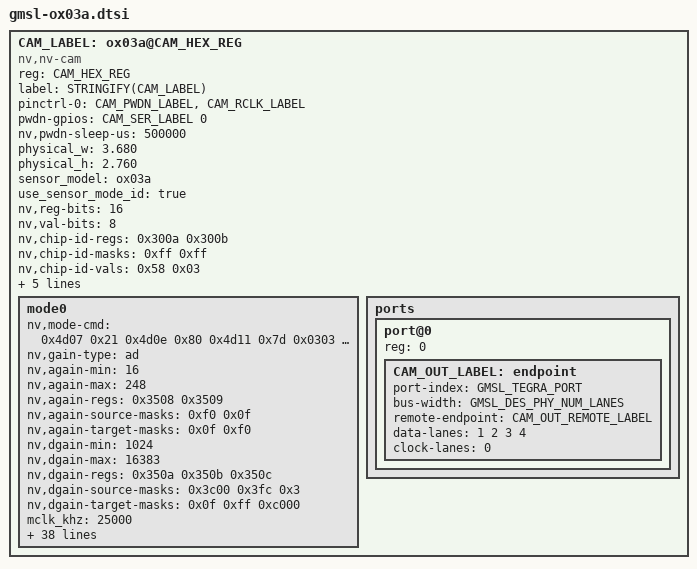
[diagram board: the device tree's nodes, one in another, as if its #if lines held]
// SPDX-License-Identifier: GPL-2.0
/*
 * Copyright (C) 2023 Analog Devices Inc.
 */

#include <dt-bindings/media/camera.h>

#if defined(CAM_INDEX)
#define CAM_VC_ID		CAM_INDEX
#define CAM_SER_INDEX		CAM_INDEX
#define CAM_SER_LABEL		CONCAT(ser_, CAM_SER_INDEX)
#define CAM_PWDN_LABEL		CONCAT(CAM_SER_LABEL, _mfp0_pwdn)
#define CAM_RCLK_LABEL		CONCAT(CAM_SER_LABEL, _mfp4_rclk)
#define CAM_OUT_LABEL		CAM_X_OUT_LABEL(CAM_INDEX)
#define CAM_LABEL		CONCAT(cam_, CAM_INDEX)
#endif

#if defined(SER_INDEX) && defined(SER_CH_INDEX)
#define CAM_OUT_REMOTE_LABEL	SER_X_CH_Y_IN_LABEL(SER_INDEX, SER_CH_INDEX)
#endif

#if !defined(CAM_HEX_REG)
#error
#endif

#if !defined(CAM_VC_ID)
#error
#endif

#if !defined(CAM_SER_LABEL)
#error
#endif

#if !defined(CAM_PWDN_LABEL)
#error
#endif

#if !defined(CAM_RCLK_LABEL)
#error
#endif

#if !defined(CAM_OUT_LABEL)
#error
#endif

#if !defined(CAM_OUT_REMOTE_LABEL)
#error
#endif

#if !defined(CAM_LABEL)
#error
#endif

// #define CAM_USE_AD_GAIN

CAM_LABEL: ox03a@CAM_HEX_REG {
	#address-cells = <1>;
	#size-cells = <0>;

	compatible = "nv,nv-cam";
	reg = <CAM_HEX_REG>;

	label = STRINGIFY(CAM_LABEL);

	pinctrl-0 = <&CAM_PWDN_LABEL &CAM_RCLK_LABEL>;
	pinctrl-names = "default";

	pwdn-gpios = <&CAM_SER_LABEL 0 GPIO_ACTIVE_HIGH>;
	nv,pwdn-sleep-us = <500000>;

	physical_w = "3.680";
	physical_h = "2.760";

	sensor_model = "ox03a";

	use_sensor_mode_id = "true";

	nv,reg-bits = <16>;
	nv,val-bits = <8>;

	nv,chip-id-regs = <0x300a 0x300b>;
	nv,chip-id-masks = <0xff 0xff>;
	nv,chip-id-vals = <0x58 0x03>;

	nv,wait-ms-cmd = <0x00>;

	nv,mode-common-cmd = <
		0x0100 0x00 /* Stream off */
		0x0103 0x01 /* SW reset */
		0x00   10   /* Wait 10ms */
	>;
	nv,start-stream-cmd = <
		0x0100 0x01 /* Stream on */
		0x00   3    /* Wait 3ms */
	>;
	nv,stop-stream-cmd = <0x0100 0x00>;

	mode0 {
		nv,mode-cmd = <
			0x4d07 0x21
			0x4d0e 0x80
			0x4d11 0x7d
			0x0303 0x02
			0x0305 0x30
			0x0306 0x03
			0x0307 0x01
			0x0316 0x00
			0x0317 0x42
			0x0323 0x02
			0x0325 0x68
			0x0326 0x00
			0x032b 0x00
			0x0400 0xe7
			0x0401 0xff
			0x0404 0x2b
			0x0405 0x32
			0x0406 0x33
			0x0407 0x8f
			0x0408 0x0c
			0x0410 0xe7
			0x0411 0xff
			0x0414 0x2b
			0x0415 0x32
			0x0416 0x33
			0x0417 0x8f
			0x0418 0x0c
			0x3002 0x03
			0x3012 0x41
			0x301e 0xb0
			0x3706 0x39
			0x370a 0x00
			0x370b 0xd1
			0x370f 0x40
			0x3711 0x22
			0x3712 0x12
			0x3713 0x00
			0x3718 0x04
			0x3719 0x3c
			0x371a 0x06
			0x371b 0x14
			0x372c 0x17
			0x3733 0x41
			0x3741 0x44
			0x3742 0x34
			0x3746 0x03
			0x374b 0x03
			0x3755 0x09
			0x376c 0x04
			0x376d 0x08
			0x376f 0x08
			0x3770 0x91
			0x3771 0x08
			0x3774 0x8a
			0x3777 0x99
			0x3779 0x22
			0x377a 0x00
			0x377b 0x00
			0x377c 0x48
			0x3785 0x08
			0x3790 0x10
			0x3793 0x00
			0x379c 0x01
			0x37a1 0x80
			0x37b3 0x0a
			0x37be 0x01
			0x37bf 0x01
			0x37c6 0x48
			0x37c7 0x38
			0x37c9 0x00
			0x37ca 0x39
			0x37cb 0x00
			0x37cc 0xa3
			0x37d1 0x39
			0x37d2 0x00
			0x37d3 0xa3
			0x37d5 0x39
			0x37d6 0x00
			0x37d7 0xa3
			0x3c06 0x29
			0x3c0b 0xa8
			0x3c53 0x68
			0x3192 0x00
			0x3193 0x00
			0x3206 0x80
			0x3216 0x01
			0x3400 0x08
			0x3409 0x02
			0x3501 0x00
			0x3502 0x40
			0x3508 0x01
			0x3509 0x00
			0x350a 0x01
			0x350b 0x00
			0x350c 0x00
			0x3548 0x01
			0x3549 0x00
			0x354a 0x01
			0x354b 0x00
			0x354c 0x00
			0x3581 0x00
			0x3582 0x40
			0x3588 0x01
			0x3589 0x00
			0x358a 0x01
			0x358b 0x00
			0x358c 0x00
			0x3600 0x00
			0x3602 0x42
			0x3603 0xf3
			0x3604 0x93
			0x3605 0xff
			0x3606 0xc0
			0x3607 0x4a
			0x360a 0xd0
			0x360b 0x0b
			0x360e 0x88
			0x3611 0x4b
			0x3612 0x4e
			0x3614 0x8a
			0x3615 0x98
			0x3619 0x00
			0x3620 0x02
			0x3626 0x0e
			0x362c 0x0e
			0x362d 0x12
			0x362e 0x0b
			0x362f 0x18
			0x3630 0x30
			0x3631 0x57
			0x3632 0x99
			0x3633 0x99
			0x3643 0x0c
			0x3644 0x00
			0x3645 0x0e
			0x3646 0x0f
			0x3647 0x0e
			0x3648 0x00
			0x3649 0x11
			0x364a 0x12
			0x364c 0x0e
			0x364d 0x0e
			0x364e 0x12
			0x364f 0x0e
			0x3652 0xc5
			0x3657 0x88
			0x3658 0x08
			0x365a 0x57
			0x365b 0x30
			0x365c 0x18
			0x365d 0x0b
			0x3660 0x01
			0x3661 0x07
			0x3662 0x00
			0x3665 0x92
			0x3666 0x13
			0x3667 0x2c
			0x3668 0x95
			0x3669 0x2c
			0x366f 0xc4
			0x3671 0x0b
			0x3673 0x6a
			0x3678 0x88
			0x3800 0x00
			0x3801 0x00
			0x3802 0x00
			0x3803 0x04
			0x3804 0x07
			0x3805 0x8f
			0x3806 0x05
			0x3807 0x0b
			0x3808 0x07
			0x3809 0x80
			0x380a 0x05
			0x380b 0x00
			0x380c 0x0a
			0x380d 0x90
			0x380e 0x05
			0x380f 0x37
			0x3810 0x00
			0x3811 0x08
			0x3813 0x04
			0x381c 0x00
			0x3820 0x44
			0x3821 0x00
			0x3822 0x14
			0x3832 0x10
			0x3833 0x01
			0x3834 0xf0
			0x383d 0x20
			0x384c 0x02
			0x384d 0x14
			0x384e 0x00
			0x384f 0x40
			0x3850 0x00
			0x3851 0x42
			0x3852 0x00
			0x3853 0x40
			0x3854 0x00
			0x3855 0x05
			0x3856 0x05
			0x3857 0x33
			0x3858 0x3c
			0x3859 0x00
			0x385a 0x03
			0x385b 0x05
			0x385c 0x32
			0x385f 0x00
			0x3860 0x10
			0x3861 0x00
			0x3862 0x40
			0x3863 0x00
			0x3864 0x40
			0x3865 0x00
			0x3866 0x40
			0x3b40 0x3e
			0x3b41 0x00
			0x3b42 0x02
			0x3b43 0x00
			0x3b44 0x00
			0x3b45 0x20
			0x3b46 0x00
			0x3b47 0x20
			0x3b84 0x05
			0x3b85 0x00
			0x3b86 0x00
			0x3b87 0x10
			0x3b88 0x00
			0x3b89 0x10
			0x3b8a 0x00
			0x3b8b 0x08
			0x3b8e 0x03
			0x3b8f 0xe8
			0x3d85 0x0b
			0x3d8c 0x70
			0x3d8d 0x26
			0x3d97 0x70
			0x3d98 0x24
			0x3d99 0x70
			0x3d9a 0x6d
			0x3d9b 0x70
			0x3d9c 0x6e
			0x3d9d 0x73
			0x3d9e 0xff
			0x3f00 0x04
			0x4001 0x2b
			0x4004 0x00
			0x4005 0x80
			0x4008 0x02
			0x4009 0x0d
			0x400a 0x10
			0x400b 0x80
			0x400f 0x80
			0x4010 0x10
			0x4011 0xbb
			0x4016 0x00
			0x4017 0x10
			0x402e 0x00
			0x402f 0x80
			0x4030 0x00
			0x4031 0x80
			0x4032 0x9f
			0x4033 0x00
			0x4308 0x00
			0x4502 0x00
			0x4507 0x16
			0x4580 0xf8
			0x4602 0x02
			0x4603 0x00
			0x460a 0x50
			0x460c 0x60
			0x4800 0x04
			0x480e 0x04
			0x4813 0x24
			0x4815 0x2b
			0x4837 0x35
			0x484b 0x27
			0x484c 0x00
			0x4886 0x00
			0x4903 0x80
			0x4f00 0xff
			0x4f01 0xff
			0x4f05 0x01
			0x5180 0x02
			0x5181 0x00
			0x5182 0x01
			0x5183 0x00
			0x5184 0x01
			0x5185 0x00
			0x5186 0x01
			0x5187 0x86
			0x51a0 0x04
			0x51a1 0x00
			0x51a2 0x04
			0x51a3 0x00
			0x51a4 0x04
			0x51a5 0x00
			0x51a6 0x04
			0x51a7 0x00
			0x51c0 0x04
			0x51c1 0x00
			0x51c2 0x04
			0x51c3 0x00
			0x51c4 0x04
			0x51c5 0x00
			0x51c6 0x04
			0x51c7 0x00
			0x5380 0x19
			0x5382 0x2e
			0x53a0 0x41
			0x53a2 0x04
			0x53a3 0x00
			0x53a4 0x04
			0x53a5 0x00
			0x53a7 0x00
			0x5400 0x19
			0x5402 0x2e
			0x5420 0x41
			0x5422 0x04
			0x5423 0x00
			0x5424 0x04
			0x5425 0x00
			0x5427 0x00
			0x5480 0x19
			0x5482 0x2e
			0x54a0 0x41
			0x54a2 0x04
			0x54a3 0x00
			0x54a4 0x04
			0x54a5 0x00
			0x54a7 0x00
			0x5800 0x38
			0x5801 0x03
			0x5802 0xc0
			0x5804 0x00
			0x5805 0x80
			0x5806 0x01
			0x5807 0x00
			0x580e 0x10
			0x5812 0x34
			0x5000 0x89
			0x5001 0x42
			0x5002 0x19
			0x5003 0x16
			0x5004 0x00
			0x5005 0x40
			0x5006 0x00
			0x5007 0x40
			0x503e 0x00
			0x503f 0x00
			0x5602 0x02
			0x5603 0x58
			0x5604 0x03
			0x5605 0x20
			0x5606 0x02
			0x5607 0x58
			0x5608 0x03
			0x5609 0x20
			0x560a 0x02
			0x560b 0x58
			0x560c 0x03
			0x560d 0x20
			0x560e 0x02
			0x560f 0x58
			0x5610 0x03
			0x5611 0x20
			0x5612 0x02
			0x5613 0x58
			0x5614 0x03
			0x5615 0x20
			0x5616 0x02
			0x5617 0x58
			0x5618 0x03
			0x5619 0x20
			0x5642 0x02
			0x5643 0x58
			0x5644 0x03
			0x5645 0x20
			0x5646 0x02
			0x5647 0x58
			0x5648 0x03
			0x5649 0x20
			0x564a 0x02
			0x564b 0x58
			0x564c 0x03
			0x564d 0x20
			0x564e 0x02
			0x564f 0x58
			0x5650 0x03
			0x5651 0x20
			0x5652 0x02
			0x5653 0x58
			0x5654 0x03
			0x5655 0x20
			0x5656 0x02
			0x5657 0x58
			0x5658 0x03
			0x5659 0x20
			0x5682 0x02
			0x5683 0x58
			0x5684 0x03
			0x5685 0x20
			0x5686 0x02
			0x5687 0x58
			0x5688 0x03
			0x5689 0x20
			0x568a 0x02
			0x568b 0x58
			0x568c 0x03
			0x568d 0x20
			0x568e 0x02
			0x568f 0x58
			0x5690 0x03
			0x5691 0x20
			0x5692 0x02
			0x5693 0x58
			0x5694 0x03
			0x5695 0x20
			0x5696 0x02
			0x5697 0x58
			0x5698 0x03
			0x5699 0x20
			0x5709 0x0f
			0x5749 0x0f
			0x5789 0x0f
			0x5200 0x70
			0x5201 0x70
			0x5202 0x73
			0x5203 0xff
			0x5205 0x6f
			0x5209 0x18
			0x520b 0x04
			0x5285 0x6f
			0x5289 0x18
			0x528b 0x04
			0x5305 0x6f
			0x5309 0x18
			0x530b 0x04
			0x3501 0x01
			0x3502 0x90
		>;
#if defined(CAM_USE_AD_GAIN)
		nv,gain-type = "ad";

		nv,again-min = <16>;
		nv,again-max = <248>;
		nv,again-regs = <0x3508 0x3509>;
		nv,again-source-masks = <0xf0 0x0f>;
		nv,again-target-masks = <0x0f 0xf0>;

		nv,dgain-min = <1024>;
		nv,dgain-max = <16383>;
		nv,dgain-regs = <0x350a 0x350b 0x350c>;
		nv,dgain-source-masks = <0x3c00 0x3fc 0x3>;
		nv,dgain-target-masks = <0x0f 0xff 0xc000>;
#else
		nv,gain-type = "simple";

		nv,gain-regs = <0x3508 0x3509>;
		nv,gain-source-masks = <0xf0 0x0f>;
		nv,gain-target-masks = <0x0f 0xf0>;
#endif

		mclk_khz = "25000";
		num_lanes = STRINGIFY(GMSL_DES_PHY_NUM_LANES);
		tegra_sinterface = GMSL_TEGRA_PORT_SERIAL;
		vc_id = STRINGIFY(CAM_VC_ID);
		phy_mode = "DPHY";
		discontinuous_clk = "no";
		dpcm_enable = "false";
		cil_settletime = "0";
#ifdef GMSL_TEGRA_LANE_POLARITY_SWAP
		lane_polarity = "6";
#endif

		active_w = "1920";
		active_h = "1280";
		mode_type = "bayer";
		pixel_phase = "bggr";
		csi_pixel_bit_depth = "12";
		readout_orientation = "0";
		line_length = "1920";
		inherent_gain = "1";
		mclk_multiplier = "10";
		pix_clk_hz = "250000000";
		serdes_link_freq = STRINGIFY(GMSL_DES_PHY_LINK_FREQ);

#if defined(CAM_USE_AD_GAIN)
		gain_factor = "16384";
		min_gain_val = "16384"; /* 1.00x */
		max_gain_val = "4062984"; /* 247.984863281x ((16 - 8/16) * (16 - 1/1024)) */
		step_gain_val = "1";
		default_gain = "16384"; /* 1.00x */
#else
		gain_factor = "16";
		min_gain_val = "16"; /* 1.00x */
		max_gain_val = "248"; /* 15.5x (16 - 1/16) */
		step_gain_val = "1";
		default_gain = "16"; /* 1.00x */
#endif

		min_hdr_ratio = "1";
		max_hdr_ratio = "1";

		framerate_factor = "1000000";
		min_framerate = "30000000"; /* 30.0 fps */
		max_framerate = "30000000"; /* 30.0 fps */
		step_framerate = "1";
		default_framerate = "30000000"; /* 30.0 fps */

		exposure_factor = "1000000";
		min_exp_time = "13"; /* us */
		max_exp_time = "683709"; /* us */
		step_exp_time = "1";
		default_exp_time = "2495"; /* us */

		embedded_metadata_height = "0";
	};

	ports {
		#address-cells = <1>;
		#size-cells = <0>;
		port@0 {
			reg = <0>;

			CAM_OUT_LABEL: endpoint {
				port-index = <GMSL_TEGRA_PORT>;
				bus-width = <GMSL_DES_PHY_NUM_LANES>;
				remote-endpoint = <&CAM_OUT_REMOTE_LABEL>;
				data-lanes = <1 2 3 4>;
				clock-lanes = <0>;
			};
		};
	};
};

#undef CAM_HEX_REG
#undef CAM_INDEX
#undef CAM_SER_INDEX
#undef CAM_SER_LABEL
#undef CAM_VC_ID
#undef CAM_PWDN_LABEL
#undef CAM_RCLK_LABEL
#undef CAM_LABEL
#undef CAM_OUT_LABEL
#undef CAM_OUT_REMOTE_LABEL
